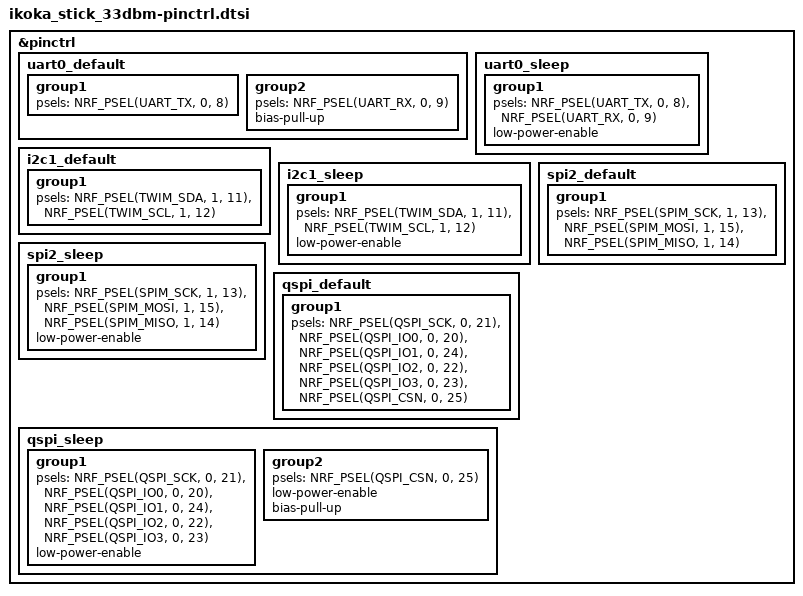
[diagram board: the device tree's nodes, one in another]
/*
 * SPDX-License-Identifier: Apache-2.0
 * Ikoka Stick 33dBm pin control - based on XIAO nRF52840
 *
 * Pin Mapping (XIAO D-pins to nRF52840 GPIOs):
 *   D0  = P0.02 (User button)   D4 = P0.04 (SX1262 NSS)   D8  = P1.13 (SCK)
 *   D1  = P0.03 (SX1262 DIO1)   D5 = P0.05 (PA RXEN)      D9  = P1.14 (MISO)
 *   D2  = P0.28 (SX1262 RESET)  D6 = P1.11 (I2C SDA)      D10 = P1.15 (MOSI)
 *   D3  = P0.29 (SX1262 BUSY)   D7 = P1.12 (I2C SCL)
 *
 * UART0 is NOT wired on this board (console is USB-CDC). The pinctrl
 * nodes below are kept so that upstream nRF52840 SoC defaults that
 * reference &uart0_default/&uart0_sleep still resolve. &uart0 itself
 * is disabled in the .dts to prevent the driver from driving pins.
 * Dummy pins P0.08 / P0.09 are not brought out to a connector on XIAO.
 */

&pinctrl {
	/* UART0 placeholder — driver is disabled, pins are not brought out */
	uart0_default: uart0_default {
		group1 {
			psels = <NRF_PSEL(UART_TX, 0, 8)>;
		};
		group2 {
			psels = <NRF_PSEL(UART_RX, 0, 9)>;
			bias-pull-up;
		};
	};

	uart0_sleep: uart0_sleep {
		group1 {
			psels = <NRF_PSEL(UART_TX, 0, 8)>,
				<NRF_PSEL(UART_RX, 0, 9)>;
			low-power-enable;
		};
	};

	/* I2C1 on D6/D7 for optional SSD1306 OLED and any external sensors */
	i2c1_default: i2c1_default {
		group1 {
			psels = <NRF_PSEL(TWIM_SDA, 1, 11)>,  /* D6 = P1.11 */
				<NRF_PSEL(TWIM_SCL, 1, 12)>; /* D7 = P1.12 */
		};
	};

	i2c1_sleep: i2c1_sleep {
		group1 {
			psels = <NRF_PSEL(TWIM_SDA, 1, 11)>,
				<NRF_PSEL(TWIM_SCL, 1, 12)>;
			low-power-enable;
		};
	};

	/* SPI2 for LoRa on D8/D9/D10 */
	spi2_default: spi2_default {
		group1 {
			psels = <NRF_PSEL(SPIM_SCK, 1, 13)>,   /* D8  = P1.13 */
				<NRF_PSEL(SPIM_MOSI, 1, 15)>,  /* D10 = P1.15 */
				<NRF_PSEL(SPIM_MISO, 1, 14)>;  /* D9  = P1.14 */
		};
	};

	spi2_sleep: spi2_sleep {
		group1 {
			psels = <NRF_PSEL(SPIM_SCK, 1, 13)>,
				<NRF_PSEL(SPIM_MOSI, 1, 15)>,
				<NRF_PSEL(SPIM_MISO, 1, 14)>;
			low-power-enable;
		};
	};

	/* QSPI for onboard flash (disabled on XIAO nRF52840 — kept for symmetry) */
	qspi_default: qspi_default {
		group1 {
			psels = <NRF_PSEL(QSPI_SCK, 0, 21)>,
				<NRF_PSEL(QSPI_IO0, 0, 20)>,
				<NRF_PSEL(QSPI_IO1, 0, 24)>,
				<NRF_PSEL(QSPI_IO2, 0, 22)>,
				<NRF_PSEL(QSPI_IO3, 0, 23)>,
				<NRF_PSEL(QSPI_CSN, 0, 25)>;
		};
	};

	qspi_sleep: qspi_sleep {
		group1 {
			psels = <NRF_PSEL(QSPI_SCK, 0, 21)>,
				<NRF_PSEL(QSPI_IO0, 0, 20)>,
				<NRF_PSEL(QSPI_IO1, 0, 24)>,
				<NRF_PSEL(QSPI_IO2, 0, 22)>,
				<NRF_PSEL(QSPI_IO3, 0, 23)>;
			low-power-enable;
		};
		group2 {
			psels = <NRF_PSEL(QSPI_CSN, 0, 25)>;
			low-power-enable;
			bias-pull-up;
		};
	};
};
